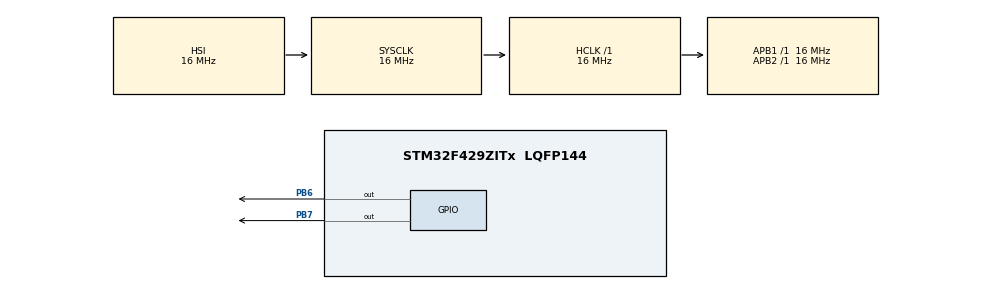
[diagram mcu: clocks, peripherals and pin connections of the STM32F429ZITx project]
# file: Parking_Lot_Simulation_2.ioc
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Mcu.Family=STM32F4
Mcu.Name=STM32F429ZITx
Mcu.Package=LQFP144
NVIC.PriorityGroup=NVIC_PRIORITYGROUP_4
PB6.Signal=GPIO_Output
PB7.Signal=GPIO_Output
ProjectManager.HeapSize=0x200
ProjectManager.StackSize=0x400
ProjectManager.TargetToolchain=STM32CubeIDE
RCC.AHBFreq_Value=16000000
RCC.APB1Freq_Value=16000000
RCC.APB2Freq_Value=16000000
RCC.CortexFreq_Value=16000000
RCC.HSE_VALUE=25000000
RCC.HSI_VALUE=16000000
RCC.LSE_VALUE=32768
RCC.SYSCLKFreq_VALUE=16000000
RCC.VCOOutputFreq_Value=192000000
board=custom

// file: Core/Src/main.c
/* USER CODE BEGIN Header */
/**
  ******************************************************************************
  * @file           : main.c
  * @brief          : Main program body
  ******************************************************************************
  * @attention
  *
  * Copyright (c) 2025 STMicroelectronics.
  * All rights reserved.
  *
  * This software is licensed under terms that can be found in the LICENSE file
  * in the root directory of this software component.
  * If no LICENSE file comes with this software, it is provided AS-IS.
  *
  ******************************************************************************
  */
/* USER CODE END Header */
#include "main.h"
#include "gpio.h"
#include "../TM1637/tm1637.h"

/* USER CODE BEGIN Includes */
volatile uint32_t parking_space_remain = 10;
volatile uint8_t exit_flag = 0;
volatile uint8_t entrance_flag = 0;
/* USER CODE END Includes */

/* USER CODE BEGIN PTD */
uint8_t name[4] = { SEG_D, SEG_E, SEG_N, SEG_N };
uint8_t help[4] = { SEG_H, SEG_E, SEG_L, SEG_P };
uint8_t full0[4] = {SEG_F, SEG_SPACE, SEG_SPACE, SEG_SPACE };
uint8_t full1[4] = {SEG_F, SEG_U, SEG_SPACE, SEG_SPACE };
uint8_t full2[4] = {SEG_F, SEG_U, SEG_L, SEG_SPACE };
uint8_t full3[4] = {SEG_F, SEG_U, SEG_L, SEG_L };
char str[6];
/* USER CODE END PTD */

/* USER CODE BEGIN PV */
void exit_led(void);
void entrance_led(void);
void display_parking_info(void);
/* USER CODE END PV */

void SystemClock_Config(void);

int main(void)
{

  /* MCU Configuration--------------------------------------------------------*/

  /* Reset of all peripherals, Initializes the Flash interface and the Systick. */
  HAL_Init();

  /* Configure the system clock */
  SystemClock_Config();

  /* Initialize all configured peripherals */
  //MX_GPIO_Init();

  /* Infinite loop */

    /* USER CODE BEGIN 3 */
  // Plan:
  // 1. Use Pins PC0 as Sensor for Exit
  // 2. Use Pins PC1 as Sensor for Entrance
  // 3. Use Pins PB2 as Output Pin to Drive Exit LED
  // 4. Use Pins PB3 as Output Pin to Drive Entrance LED

  	RCC -> AHB1ENR  = 0x04;						// Configure Port C
  	RCC -> AHB1ENR |= 0x02;						// Configure Port B

	RCC-> AHB1ENR  |= 0x40;						// Configure Port G, Port B, Port A, and Port C
	GPIOG -> MODER |= 0x24000000;				// Configure PG13 and PG14 as output
  	GPIOG -> ODR |= 0x00002000;				// On board LED PG13 - testing
  	GPIOG -> ODR |= 0x00004000;				// On board LED PG14 - testing

	GPIOC -> MODER &= 0xFFFFFFF0;				// Mask the irrelevant pins
	GPIOC -> MODER |= 0x00000000;				// Configure PC0 and PC1 as input pins

	GPIOB -> MODER &= 0xFFFFFF0F;				// Mask the irrelevant pins
	GPIOB -> MODER |= 0x00000050;				// Configure PB2 and PB3 as output pins
	GPIOB -> PUPDR |= 0x000000A0; 				// Pull down PB2 and PB3 (Optional)

	RCC -> APB2ENR = 0x4000;
	SYSCFG -> EXTICR[0] = 0x0022;
	EXTI -> IMR = 0x0003;
	EXTI -> RTSR = 0x0003;
	NVIC_EnableIRQ(EXTI0_IRQn);
	NVIC_EnableIRQ(EXTI1_IRQn);

	// Initialize TM1637: Clock -> PB6, Data -> PB7
	tm1637_init(GPIOB, GPIO_PIN_6, GPIOB, GPIO_PIN_7);

	// Set brightness (1-8)
	tm1637_set_brightness(5);

	tm1637_show_segments(name);  // Displays Name
	HAL_Delay(1000);

	// Sensors are active low: If Input States are HIGH -> NO DETECTION
	// If Input States are HIGH: Exit/ Entrance LEDs are not lit
	while(1){

		if(parking_space_remain == 0){
			tm1637_show_segments(full0);  // Displays Name
			HAL_Delay(500);
			tm1637_show_segments(full1);  // Displays Name
			HAL_Delay(500);
			tm1637_show_segments(full2);  // Displays Name
			HAL_Delay(500);
			tm1637_show_segments(full3);  // Displays Name
			HAL_Delay(500);
		}
		else{
			uint8_to_spaced_string(parking_space_remain, str);
			tm1637_show_digits(str);
		}
		/*
		GPIOG -> ODR |= 0x00002000;				// On board LED PG13 - testing
		HAL_Delay(500);
		GPIOG -> ODR &= ~(0x00002000);				// On board LED PG13 - testing
		HAL_Delay(500);*/
		display_parking_info();

		if(exit_flag == 1){
			exit_led();
		}
		if(entrance_flag == 1){
			entrance_led();
		}
	}

	// Deprecated
	/*
  while (1)
  {
	if((GPIOC -> IDR & (1<<0)) == 0b00000000)
	{
		GPIOB->ODR |= (1 << 2);
		// If exit == 1
		parking_space_remain --;
		//HAL_Delay(10);
	}
	else
	{
		GPIOB->ODR &= (0 << 2);
	}

	if((GPIOC -> IDR & (1<<1)) == 0b00000000)
	{
		GPIOB->ODR |= (1 << 3);
		parking_space_remain ++;
		//HAL_Delay(10);
	}
	else
	{
		GPIOB->ODR &= (0 << 3);
	}

  }*/
  /* USER CODE END 3 */
}

void SystemClock_Config(void)
{
  RCC_OscInitTypeDef RCC_OscInitStruct = {0};
  RCC_ClkInitTypeDef RCC_ClkInitStruct = {0};

  /** Configure the main internal regulator output voltage
  */
  __HAL_RCC_PWR_CLK_ENABLE();
  __HAL_PWR_VOLTAGESCALING_CONFIG(PWR_REGULATOR_VOLTAGE_SCALE3);

  /** Initializes the RCC Oscillators according to the specified parameters
  * in the RCC_OscInitTypeDef structure.
  */
  RCC_OscInitStruct.OscillatorType = RCC_OSCILLATORTYPE_HSI;
  RCC_OscInitStruct.HSIState = RCC_HSI_ON;
  RCC_OscInitStruct.HSICalibrationValue = RCC_HSICALIBRATION_DEFAULT;
  RCC_OscInitStruct.PLL.PLLState = RCC_PLL_NONE;
  if (HAL_RCC_OscConfig(&RCC_OscInitStruct) != HAL_OK)
  {
    Error_Handler();
  }

  /** Initializes the CPU, AHB and APB buses clocks
  */
  RCC_ClkInitStruct.ClockType = RCC_CLOCKTYPE_HCLK|RCC_CLOCKTYPE_SYSCLK
                              |RCC_CLOCKTYPE_PCLK1|RCC_CLOCKTYPE_PCLK2;
  RCC_ClkInitStruct.SYSCLKSource = RCC_SYSCLKSOURCE_HSI;
  RCC_ClkInitStruct.AHBCLKDivider = RCC_SYSCLK_DIV1;
  RCC_ClkInitStruct.APB1CLKDivider = RCC_HCLK_DIV1;
  RCC_ClkInitStruct.APB2CLKDivider = RCC_HCLK_DIV1;

  if (HAL_RCC_ClockConfig(&RCC_ClkInitStruct, FLASH_LATENCY_0) != HAL_OK)
  {
    Error_Handler();
  }
}

/* USER CODE BEGIN 4 */
void exit_led(void){
			GPIOB->ODR |= (1 << 2);
			HAL_Delay(1000);
			GPIOB->ODR &= (0 << 2);
			exit_flag = 0;
}

void entrance_led(void){
			GPIOB->ODR |= (1 << 3);
			HAL_Delay(1000);
			GPIOB->ODR &= (0 << 3);
			entrance_flag = 0;
}

void display_parking_info(void){

		// TODO
}
/* USER CODE END 4 */

void Error_Handler(void)
{
  __disable_irq();
  while (1)
  {
  }
}
